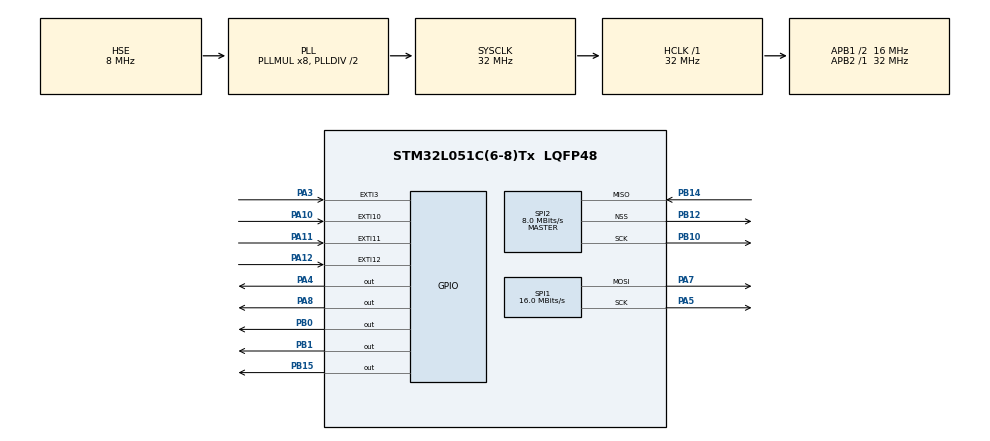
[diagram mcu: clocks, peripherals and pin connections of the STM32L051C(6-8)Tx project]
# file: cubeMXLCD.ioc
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Dma.Request0=SPI2_RX
Dma.Request1=SPI1_TX
Dma.SPI1_TX.1.Direction=DMA_MEMORY_TO_PERIPH
Dma.SPI1_TX.1.Instance=DMA1_Channel3
Dma.SPI1_TX.1.MemDataAlignment=DMA_MDATAALIGN_BYTE
Dma.SPI1_TX.1.MemInc=DMA_MINC_ENABLE
Dma.SPI1_TX.1.Mode=DMA_NORMAL
Dma.SPI1_TX.1.PeriphDataAlignment=DMA_PDATAALIGN_BYTE
Dma.SPI1_TX.1.PeriphInc=DMA_PINC_DISABLE
Dma.SPI1_TX.1.Priority=DMA_PRIORITY_VERY_HIGH
Dma.SPI2_RX.0.Direction=DMA_PERIPH_TO_MEMORY
Dma.SPI2_RX.0.Instance=DMA1_Channel4
Dma.SPI2_RX.0.MemDataAlignment=DMA_MDATAALIGN_HALFWORD
Dma.SPI2_RX.0.MemInc=DMA_MINC_ENABLE
Dma.SPI2_RX.0.Mode=DMA_NORMAL
Dma.SPI2_RX.0.PeriphDataAlignment=DMA_PDATAALIGN_HALFWORD
Dma.SPI2_RX.0.PeriphInc=DMA_PINC_DISABLE
Dma.SPI2_RX.0.Priority=DMA_PRIORITY_VERY_HIGH
Mcu.Family=STM32L0
Mcu.Name=STM32L051C(6-8)Tx
Mcu.Package=LQFP48
NVIC.DMA1_Channel2_3_IRQn=true\:0\:0\:false\:false\:true
NVIC.DMA1_Channel4_5_6_7_IRQn=true\:0\:0\:false\:false\:true
NVIC.TIM6_DAC_IRQn=true\:0\:0\:false\:false\:true
PA10.Signal=GPXTI10
PA11.Signal=GPXTI11
PA12.Signal=GPXTI12
PA13.Mode=Serial_Wire
PA13.Signal=SYS_SWDIO
PA14.Mode=Serial_Wire
PA14.Signal=SYS_SWCLK
PA3.Signal=GPXTI3
PA4.GPIO_PuPd=GPIO_PULLDOWN
PA4.GPIO_Speed=GPIO_SPEED_FREQ_VERY_HIGH
PA4.Signal=GPIO_Output
PA5.Mode=TX_Only_Simplex_Unidirect_Master
PA5.Signal=SPI1_SCK
PA7.Mode=TX_Only_Simplex_Unidirect_Master
PA7.Signal=SPI1_MOSI
PA8.Signal=GPIO_Output
PB0.Signal=GPIO_Output
PB1.Signal=GPIO_Output
PB10.GPIO_PuPd=GPIO_NOPULL
PB10.Mode=RX_Only_Simplex_Unidirect_Master
PB10.Signal=SPI2_SCK
PB12.GPIO_PuPd=GPIO_NOPULL
PB12.Mode=NSS_Signal_Hard_Output
PB12.Signal=SPI2_NSS
PB14.GPIO_PuPd=GPIO_NOPULL
PB14.Mode=RX_Only_Simplex_Unidirect_Master
PB14.Signal=SPI2_MISO
PB15.Signal=GPIO_Output
PH0-OSC_IN.Mode=HSE-External-Oscillator
PH0-OSC_IN.Signal=RCC_OSC_IN
PH1-OSC_OUT.Mode=HSE-External-Oscillator
PH1-OSC_OUT.Signal=RCC_OSC_OUT
ProjectManager.HeapSize=0x200
ProjectManager.StackSize=0x400
ProjectManager.TargetToolchain=MDK-ARM V5
RCC.ADCFreq_Value=16000000
RCC.AHBFreq_Value=32000000
RCC.APB1CLKDivider=RCC_HCLK_DIV2
RCC.APB1Freq_Value=16000000
RCC.APB1TimFreq_Value=32000000
RCC.APB2Freq_Value=32000000
RCC.APB2TimFreq_Value=32000000
RCC.HCLKFreq_Value=32000000
RCC.HSE_VALUE=8000000
RCC.HSI16_VALUE=16000000
RCC.HSI_VALUE=16000000
RCC.LSE_VALUE=32768
RCC.LptimClockSelection=RCC_LPTIM1CLKSOURCE_LSI
RCC.MSI_VALUE=2097000
RCC.PLLMUL=RCC_PLLMUL_8
RCC.PLLSourceVirtual=RCC_PLLSOURCE_HSE
RCC.SYSCLKFreq_VALUE=32000000
RCC.SYSCLKSource=RCC_SYSCLKSOURCE_PLLCLK
RCC.VCOOutputFreq_Value=64000000
RCC.VDD_VALUE=3.3
SPI1.BaudRatePrescaler=SPI_BAUDRATEPRESCALER_2
SPI1.CalculateBaudRate=16.0 MBits/s
SPI1.Mode=SPI_MODE_MASTER
SPI1.NSSPMode=SPI_NSS_PULSE_DISABLE
SPI2.BaudRatePrescaler=SPI_BAUDRATEPRESCALER_2
SPI2.CLKPhase=SPI_PHASE_2EDGE
SPI2.CLKPolarity=SPI_POLARITY_HIGH
SPI2.CalculateBaudRate=8.0 MBits/s
SPI2.DataSize=SPI_DATASIZE_16BIT
SPI2.Direction=SPI_DIRECTION_2LINES_RXONLY
SPI2.FirstBit=SPI_FIRSTBIT_MSB
SPI2.Mode=SPI_MODE_MASTER
SPI2.VirtualNSS=VM_NSSHARD
TIM6.Period=10000
TIM6.Prescaler=3200
VP_IWDG_VS_IWDG.Mode=IWDG_Activate
VP_TIM6_VS_ClockSourceINT.Mode=Enable_Timer
board=cubeMXLCD

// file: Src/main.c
/**
  ******************************************************************************
  * File Name          : main.c
  * Description        : Main program body
  ******************************************************************************
  *
  * COPYRIGHT(c) 2016 STMicroelectronics
  *
  * Redistribution and use in source and binary forms, with or without modification,
  * are permitted provided that the following conditions are met:
  *   1. Redistributions of source code must retain the above copyright notice,
  *      this list of conditions and the following disclaimer.
  *   2. Redistributions in binary form must reproduce the above copyright notice,
  *      this list of conditions and the following disclaimer in the documentation
  *      and/or other materials provided with the distribution.
  *   3. Neither the name of STMicroelectronics nor the names of its contributors
  *      may be used to endorse or promote products derived from this software
  *      without specific prior written permission.
  *
  * THIS SOFTWARE IS PROVIDED BY THE COPYRIGHT HOLDERS AND CONTRIBUTORS "AS IS"
  * AND ANY EXPRESS OR IMPLIED WARRANTIES, INCLUDING, BUT NOT LIMITED TO, THE
  * IMPLIED WARRANTIES OF MERCHANTABILITY AND FITNESS FOR A PARTICULAR PURPOSE ARE
  * DISCLAIMED. IN NO EVENT SHALL THE COPYRIGHT HOLDER OR CONTRIBUTORS BE LIABLE
  * FOR ANY DIRECT, INDIRECT, INCIDENTAL, SPECIAL, EXEMPLARY, OR CONSEQUENTIAL
  * DAMAGES (INCLUDING, BUT NOT LIMITED TO, PROCUREMENT OF SUBSTITUTE GOODS OR
  * SERVICES; LOSS OF USE, DATA, OR PROFITS; OR BUSINESS INTERRUPTION) HOWEVER
  * CAUSED AND ON ANY THEORY OF LIABILITY, WHETHER IN CONTRACT, STRICT LIABILITY,
  * OR TORT (INCLUDING NEGLIGENCE OR OTHERWISE) ARISING IN ANY WAY OUT OF THE USE
  * OF THIS SOFTWARE, EVEN IF ADVISED OF THE POSSIBILITY OF SUCH DAMAGE.
  *
  ******************************************************************************
  */
#include "stm32l0xx_hal.h"

/* USER CODE BEGIN Includes */
#include "flir_lcd.h"
#include "flir_display.h"

#include <string.h>

/* USER CODE END Includes */

IWDG_HandleTypeDef hiwdg;

SPI_HandleTypeDef hspi1;
SPI_HandleTypeDef hspi2;
DMA_HandleTypeDef hdma_spi1_tx;
DMA_HandleTypeDef hdma_spi2_rx;

TIM_HandleTypeDef htim6;

/* USER CODE BEGIN PV */
/* Private variables ---------------------------------------------------------*/

/* USER CODE END PV */

void SystemClock_Config(void);
void Error_Handler(void);
static void MX_GPIO_Init(void);
static void MX_DMA_Init(void);
static void MX_IWDG_Init(void);
static void MX_SPI1_Init(void);
static void MX_SPI2_Init(void);
static void MX_TIM6_Init(void);

/* USER CODE BEGIN PFP */
/* Private function prototypes -----------------------------------------------*/

/* USER CODE END PFP */

/* USER CODE BEGIN 0 */
uint8_t test,test1,test2;
uint16_t testbuf[LCD_FLIR_RX_BUF_SIZ];
/* USER CODE END 0 */

int main(void)
{

  /* MCU Configuration----------------------------------------------------------*/

  /* Reset of all peripherals, Initializes the Flash interface and the Systick. */
  HAL_Init();

  /* Configure the system clock */
  SystemClock_Config();

  /* Initialize all configured peripherals */
  MX_GPIO_Init();
  MX_DMA_Init();
  MX_IWDG_Init();
  MX_SPI1_Init();
  MX_SPI2_Init();
  MX_TIM6_Init();

  /* USER CODE BEGIN 2 */
	HAL_NVIC_SetPriority(TIM6_IRQn, 0, 0);
  HAL_NVIC_EnableIRQ(TIM6_IRQn);
	HAL_TIM_Base_Start_IT(&htim6);

	// Init LCD
	// Init LCD and also control parameters
	initFlir_Display();

	// init LCD
	// LCD_Init();

	// flir_display_startRec();
  /* USER CODE END 2 */

  /* Infinite loop */
  while (1)
  {

  /* USER CODE BEGIN 3 */

	// if receiving finish, check and responce
		if(flir_RXCpl)
		{
			flir_display_recDataCheck();
		}

  }
  /* USER CODE END 3 */

}

/** System Clock Configuration
*/
void SystemClock_Config(void)
{

  RCC_OscInitTypeDef RCC_OscInitStruct;
  RCC_ClkInitTypeDef RCC_ClkInitStruct;

  __HAL_RCC_PWR_CLK_ENABLE();

  __HAL_PWR_VOLTAGESCALING_CONFIG(PWR_REGULATOR_VOLTAGE_SCALE1);

  RCC_OscInitStruct.OscillatorType = RCC_OSCILLATORTYPE_LSI|RCC_OSCILLATORTYPE_HSE;
  RCC_OscInitStruct.HSEState = RCC_HSE_ON;
  RCC_OscInitStruct.LSIState = RCC_LSI_ON;
  RCC_OscInitStruct.PLL.PLLState = RCC_PLL_ON;
  RCC_OscInitStruct.PLL.PLLSource = RCC_PLLSOURCE_HSE;
  RCC_OscInitStruct.PLL.PLLMUL = RCC_PLLMUL_8;
  RCC_OscInitStruct.PLL.PLLDIV = RCC_PLLDIV_2;
  if (HAL_RCC_OscConfig(&RCC_OscInitStruct) != HAL_OK)
  {
    Error_Handler();
  }

  RCC_ClkInitStruct.ClockType = RCC_CLOCKTYPE_HCLK|RCC_CLOCKTYPE_SYSCLK
                              |RCC_CLOCKTYPE_PCLK1|RCC_CLOCKTYPE_PCLK2;
  RCC_ClkInitStruct.SYSCLKSource = RCC_SYSCLKSOURCE_PLLCLK;
  RCC_ClkInitStruct.AHBCLKDivider = RCC_SYSCLK_DIV1;
  RCC_ClkInitStruct.APB1CLKDivider = RCC_HCLK_DIV2;
  RCC_ClkInitStruct.APB2CLKDivider = RCC_HCLK_DIV1;
  if (HAL_RCC_ClockConfig(&RCC_ClkInitStruct, FLASH_LATENCY_1) != HAL_OK)
  {
    Error_Handler();
  }

  HAL_SYSTICK_Config(HAL_RCC_GetHCLKFreq()/1000);

  HAL_SYSTICK_CLKSourceConfig(SYSTICK_CLKSOURCE_HCLK);

  /* SysTick_IRQn interrupt configuration */
  HAL_NVIC_SetPriority(SysTick_IRQn, 0, 0);
}

/* IWDG init function */
static void MX_IWDG_Init(void)
{

  hiwdg.Instance = IWDG;
  hiwdg.Init.Prescaler = IWDG_PRESCALER_4;
  hiwdg.Init.Window = 4095;
  hiwdg.Init.Reload = 4095;
  if (HAL_IWDG_Init(&hiwdg) != HAL_OK)
  {
    Error_Handler();
  }

}

/* SPI1 init function */
static void MX_SPI1_Init(void)
{

  hspi1.Instance = SPI1;
  hspi1.Init.Mode = SPI_MODE_MASTER;
  hspi1.Init.Direction = SPI_DIRECTION_2LINES;
  hspi1.Init.DataSize = SPI_DATASIZE_8BIT;
  hspi1.Init.CLKPolarity = SPI_POLARITY_LOW;
  hspi1.Init.CLKPhase = SPI_PHASE_1EDGE;
  hspi1.Init.NSS = SPI_NSS_SOFT;
  hspi1.Init.BaudRatePrescaler = SPI_BAUDRATEPRESCALER_2;
  hspi1.Init.FirstBit = SPI_FIRSTBIT_MSB;
  hspi1.Init.TIMode = SPI_TIMODE_DISABLE;
  hspi1.Init.CRCCalculation = SPI_CRCCALCULATION_DISABLE;
  hspi1.Init.CRCPolynomial = 7;
  if (HAL_SPI_Init(&hspi1) != HAL_OK)
  {
    Error_Handler();
  }

}

/* SPI2 init function */
static void MX_SPI2_Init(void)
{

  hspi2.Instance = SPI2;
  hspi2.Init.Mode = SPI_MODE_MASTER;
  hspi2.Init.Direction = SPI_DIRECTION_2LINES_RXONLY;
  hspi2.Init.DataSize = SPI_DATASIZE_16BIT;
  hspi2.Init.CLKPolarity = SPI_POLARITY_HIGH;
  hspi2.Init.CLKPhase = SPI_PHASE_2EDGE;
  hspi2.Init.NSS = SPI_NSS_HARD_OUTPUT;
  hspi2.Init.BaudRatePrescaler = SPI_BAUDRATEPRESCALER_2;
  hspi2.Init.FirstBit = SPI_FIRSTBIT_MSB;
  hspi2.Init.TIMode = SPI_TIMODE_DISABLE;
  hspi2.Init.CRCCalculation = SPI_CRCCALCULATION_DISABLE;
  hspi2.Init.CRCPolynomial = 7;
  if (HAL_SPI_Init(&hspi2) != HAL_OK)
  {
    Error_Handler();
  }

}

/* TIM6 init function */
static void MX_TIM6_Init(void)
{

  TIM_MasterConfigTypeDef sMasterConfig;

  htim6.Instance = TIM6;
  htim6.Init.Prescaler = 3200;
  htim6.Init.CounterMode = TIM_COUNTERMODE_UP;
  htim6.Init.Period = 10000;
  if (HAL_TIM_Base_Init(&htim6) != HAL_OK)
  {
    Error_Handler();
  }

  sMasterConfig.MasterOutputTrigger = TIM_TRGO_RESET;
  sMasterConfig.MasterSlaveMode = TIM_MASTERSLAVEMODE_DISABLE;
  if (HAL_TIMEx_MasterConfigSynchronization(&htim6, &sMasterConfig) != HAL_OK)
  {
    Error_Handler();
  }

}

static void MX_DMA_Init(void)
{
  /* DMA controller clock enable */
  __HAL_RCC_DMA1_CLK_ENABLE();

  /* DMA interrupt init */
  /* DMA1_Channel2_3_IRQn interrupt configuration */
  HAL_NVIC_SetPriority(DMA1_Channel2_3_IRQn, 0, 0);
  HAL_NVIC_EnableIRQ(DMA1_Channel2_3_IRQn);
  /* DMA1_Channel4_5_6_7_IRQn interrupt configuration */
  HAL_NVIC_SetPriority(DMA1_Channel4_5_6_7_IRQn, 0, 0);
  HAL_NVIC_EnableIRQ(DMA1_Channel4_5_6_7_IRQn);

}

/** Configure pins as
        * Analog
        * Input
        * Output
        * EVENT_OUT
        * EXTI
*/
static void MX_GPIO_Init(void)
{

  GPIO_InitTypeDef GPIO_InitStruct;

  /* GPIO Ports Clock Enable */
  __HAL_RCC_GPIOH_CLK_ENABLE();
  __HAL_RCC_GPIOA_CLK_ENABLE();
  __HAL_RCC_GPIOB_CLK_ENABLE();

  /*Configure GPIO pins : PA3 PA10 PA11 PA12 */
  GPIO_InitStruct.Pin = GPIO_PIN_3|GPIO_PIN_10|GPIO_PIN_11|GPIO_PIN_12;
  GPIO_InitStruct.Mode = GPIO_MODE_IT_RISING;
  GPIO_InitStruct.Pull = GPIO_NOPULL;
  HAL_GPIO_Init(GPIOA, &GPIO_InitStruct);

  /*Configure GPIO pin : PA4 */
  GPIO_InitStruct.Pin = GPIO_PIN_4;
  GPIO_InitStruct.Mode = GPIO_MODE_OUTPUT_PP;
  GPIO_InitStruct.Pull = GPIO_PULLDOWN;
  GPIO_InitStruct.Speed = GPIO_SPEED_FREQ_VERY_HIGH;
  HAL_GPIO_Init(GPIOA, &GPIO_InitStruct);

  /*Configure GPIO pins : PB0 PB1 PB15 */
  GPIO_InitStruct.Pin = GPIO_PIN_0|GPIO_PIN_1|GPIO_PIN_15;
  GPIO_InitStruct.Mode = GPIO_MODE_OUTPUT_PP;
  GPIO_InitStruct.Pull = GPIO_NOPULL;
  GPIO_InitStruct.Speed = GPIO_SPEED_FREQ_LOW;
  HAL_GPIO_Init(GPIOB, &GPIO_InitStruct);

  /*Configure GPIO pin : PA8 */
  GPIO_InitStruct.Pin = GPIO_PIN_8;
  GPIO_InitStruct.Mode = GPIO_MODE_OUTPUT_PP;
  GPIO_InitStruct.Pull = GPIO_NOPULL;
  GPIO_InitStruct.Speed = GPIO_SPEED_FREQ_LOW;
  HAL_GPIO_Init(GPIOA, &GPIO_InitStruct);

  /*Configure GPIO pin Output Level */
  HAL_GPIO_WritePin(GPIOA, GPIO_PIN_4|GPIO_PIN_8, GPIO_PIN_RESET);

  /*Configure GPIO pin Output Level */
  HAL_GPIO_WritePin(GPIOB, GPIO_PIN_0|GPIO_PIN_1|GPIO_PIN_15, GPIO_PIN_RESET);

}

void Error_Handler(void)
{
  while(1)
  {
  }
}

/************************ (C) COPYRIGHT STMicroelectronics *****END OF FILE****/
